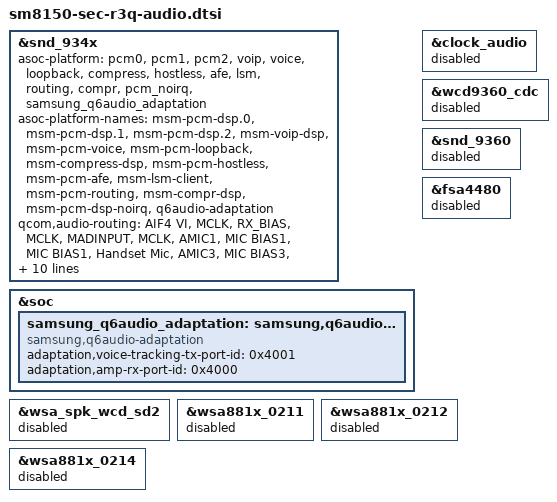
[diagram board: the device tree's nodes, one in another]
/* Copyright (c) 2016-2017, The Linux Foundation. All rights reserved.
 *
 * This program is free software; you can redistribute it and/or modify
 * it under the terms of the GNU General Public License version 2 and
 * only version 2 as published by the Free Software Foundation.
 *
 * This program is distributed in the hope that it will be useful,
 * but WITHOUT ANY WARRANTY; without even the implied warranty of
 * MERCHANTABILITY or FITNESS FOR A PARTICULAR PURPOSE.  See the
 * GNU General Public License for more details.
 */

#include "../qcom/sm8150-audio-overlay.dtsi"

&snd_934x {
	asoc-platform = <&pcm0>, <&pcm1>, <&pcm2>, <&voip>, <&voice>,
			<&loopback>, <&compress>, <&hostless>,
			<&afe>, <&lsm>, <&routing>, <&compr>,
			<&pcm_noirq>, <&samsung_q6audio_adaptation>;
	asoc-platform-names = "msm-pcm-dsp.0", "msm-pcm-dsp.1",
			"msm-pcm-dsp.2", "msm-voip-dsp",
			"msm-pcm-voice", "msm-pcm-loopback",
			"msm-compress-dsp", "msm-pcm-hostless",
			"msm-pcm-afe", "msm-lsm-client",
			"msm-pcm-routing", "msm-compr-dsp",
			"msm-pcm-dsp-noirq", "q6audio-adaptation";
	qcom,audio-routing =
		"AIF4 VI", "MCLK",
		"RX_BIAS", "MCLK",
		"MADINPUT", "MCLK",
		"AMIC1", "MIC BIAS1",
		"MIC BIAS1", "Handset Mic",
		"AMIC3", "MIC BIAS3",
		"MIC BIAS3", "Sub Mic",
		"AMIC2", "MIC BIAS2",
		"SpkrLeft IN", "SPK1 OUT";

	qcom,wcn-btfm = <1>;
	qcom,hph-en1-gpio = <0>;
	qcom,hph-en0-gpio = <0>;
	fsa4480-i2c-handle = <0>;
	qcom,wsa-max-devs = <1>;
	pm_qos_noise_wa = <1>;
	qcom,wsa-devs = <&wsa881x_70213>;
	qcom,wsa-aux-dev-prefix = "SpkrLeft";
};

&soc {
	samsung_q6audio_adaptation: samsung,q6audio-adaptation {
		compatible = "samsung,q6audio-adaptation";
		adaptation,voice-tracking-tx-port-id = <0x4001>;
		adaptation,amp-rx-port-id = <0x4000>;
	};
};

&clock_audio {
	status = "disabled";
};

&wcd9360_cdc {
	status = "disabled";
};

&snd_9360 {
	status = "disabled";
};

&fsa4480 {
	status = "disabled";
};

&wsa_spk_wcd_sd2 {
	status = "disabled";
};

&wsa881x_0211 {
	status = "disabled";
};

&wsa881x_0212 {
	status = "disabled";
};

&wsa881x_0214 {
	status = "disabled";
};

